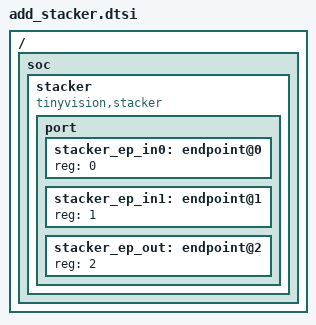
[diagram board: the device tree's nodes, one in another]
/*
 * Copyright (c) 2025 tinyVision.ai Inc.
 *
 * SPDX-License-Identifier: Apache-2.0
 */

/ {
	soc {
		stacker: stacker {
			compatible = "tinyvision,stacker";

			port {
				#address-cells = <1>;
				#size-cells = <0>;

				stacker_ep_in0: endpoint@0 {
					reg = <0>;
				};

				stacker_ep_in1: endpoint@1 {
					reg = <1>;
				};

				stacker_ep_out: endpoint@2 {
					reg = <2>;
				};
			};
		};
	};
};
